# PN74xxAU register map
File version: 2
CPU: CM0 r0p0, little endian, no MPU, no FPU, 2 interrupt priority bits
Registers are 32-bit, read-write, reset 0x0 unless marked. A register's access mark holds for its fields unless they carry their own. Offsets are from the block's base; [hi:lo] are bit positions; {n}, {i} and the like mark numbered series.

## PCR — Power Control and Reset
Base 0x40024000
{0x0+4i} PCR_GPREG{i}_REG (i=0..2) — General purpose register {i} for SW
  [31:0] PCR_GPREG{i} — General Purpose Register for SW
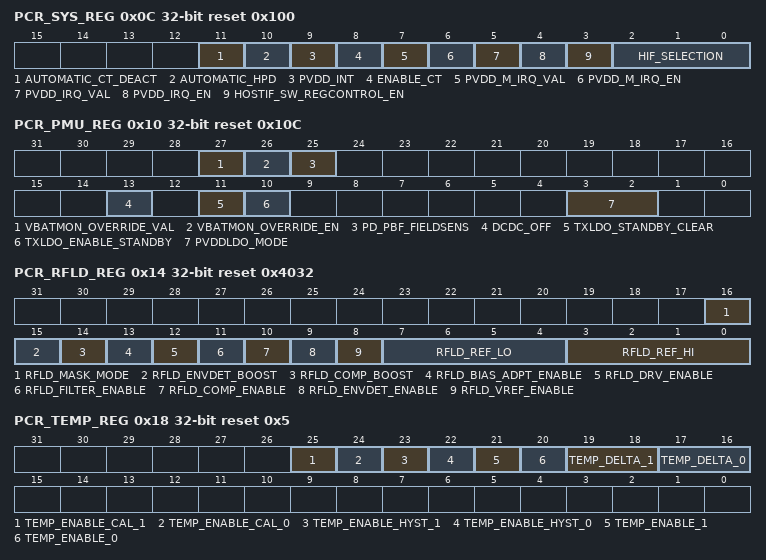
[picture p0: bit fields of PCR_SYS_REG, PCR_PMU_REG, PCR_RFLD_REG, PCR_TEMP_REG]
0x0C PCR_SYS_REG reset 0x100 — System configuration like Hostif selection and CT enabling
  [11] AUTOMATIC_CT_DEACT — Enables automatic initiation of ct deactivation sequence when VBUSP voltage goes below programmed range.
  [10] AUTOMATIC_HPD — Enables PCR to go automatically into HPD state when the VBUS voltage goes below programmed voltage of 2.3V/2.7V
  [9] PVDD_INT — Indicatres that PVDD is being supplied using internal PVDD LDO
  [8] ENABLE_CT — enables the Contact interface.
  [7] PVDD_M_IRQ_VAL — Selects the PVDD_M voltage trigger level
  [6] PVDD_M_IRQ_EN — Enables the PVDD_M IRQ
  [5] PVDD_IRQ_VAL — Selects the PVDD voltage trigger level
  [4] PVDD_IRQ_EN — Enables the PVDD IRQ
  [3] HOSTIF_SW_REGCONTROL_EN — Enabled control of USB D+,D- from ATX_A/B registers
  [2:0] HIF_SELECTION — Host Interface Selection
0x10 PCR_PMU_REG reset 0x10C — PMU interface. For LDO, bandgap,DCDC configuration and sequences
  [27] VBATMON_OVERRIDE_VAL — 0 for 2.7V and 1 for 2.3V
  [26] VBATMON_OVERRIDE_EN — enable for vbus monitor
  [25] PD_PBF_FIELDSENS — Enable for pbf_pd_fieldsens
  [13] DCDC_OFF — To set the DC-DC in high impedance state enabling the testing of VCCLDO. VUP will be forced from outside.
  [11] TXLDO_STANDBY_CLEAR — TXLDO clear standby mode
  [10] TXLDO_ENABLE_STANDBY — TXLDO enable standby mode
  [3:2] PVDDLDO_MODE — Selects pvddldo mode normal/low power/soft start/power down
0x14 PCR_RFLD_REG reset 0x4032 — CLIF configuration
  [16] RFLD_MASK_MODE — RFU
  [15] RFLD_ENVDET_BOOST — Higher bias current for the env-detector
  [14] RFLD_COMP_BOOST — Higher bias current for comparator
  [13] RFLD_BIAS_ADPT_ENABLE — Enable of automatic bias current regulation
  [12] RFLD_DRV_ENABLE — Enable the chopper clock driver for the RF Level Detector.
  [11] RFLD_FILTER_ENABLE — Enable the chopper fillter for RF Level Detector
  [10] RFLD_COMP_ENABLE — Enable of RFLD comparator
  [9] RFLD_ENVDET_ENABLE — Enable of RFLD envelope detector
  [8] RFLD_VREF_ENABLE — Enable for RFLD reference voltage generator
  [7:4] RFLD_REF_LO — Higher Reference Value for RF Level Detector
  [3:0] RFLD_REF_HI — Lower Reference Value for RF Level Detector
0x18 PCR_TEMP_REG reset 0x5 — Temperature sensor calibration information
  [25] TEMP_ENABLE_CAL_1 — Enable Calibration of Temperature Sensor 2
  [24] TEMP_ENABLE_CAL_0 — Enable Calibration of Temperature Sensor 1
  [23] TEMP_ENABLE_HYST_1 — Enable Hystere of Temperature Sensor 2
  [22] TEMP_ENABLE_HYST_0 — Enable Hystere of Temperature Sensor 1
  [21] TEMP_ENABLE_1 — Enable Temp Sensor 2
  [20] TEMP_ENABLE_0 — Enable Temp Sensor 1
  [19:18] TEMP_DELTA_1 — selects temperatur threshold detection for temperature sensor 2
  [17:16] TEMP_DELTA_0 — selects temperatur threshold detection for temperature sensor 1
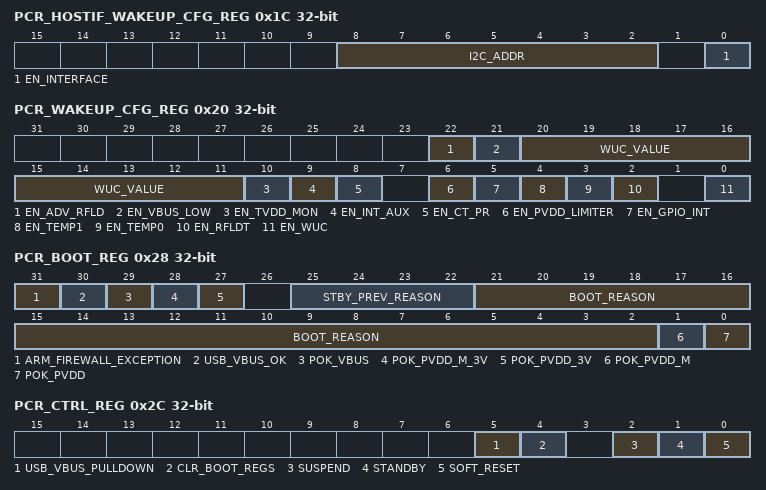
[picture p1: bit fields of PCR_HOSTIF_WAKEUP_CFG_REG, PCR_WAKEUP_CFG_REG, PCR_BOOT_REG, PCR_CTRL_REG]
0x1C PCR_HOSTIF_WAKEUP_CFG_REG — Configuring Wakeup source for Standby and Suspend
  [8:2] I2C_ADDR — I2C address for wakeup
  [0] EN_INTERFACE — Enable Wakeup Host Interface
0x20 PCR_WAKEUP_CFG_REG — Configuring Wakeup source for Standby and Suspend
  [22] EN_ADV_RFLD — Enable Advanced RF Level Detector
  [21] EN_VBUS_LOW — Enable wakeup when vbus goes low
  [20:11] WUC_VALUE — Wakeup Timer Value
  [10] EN_TVDD_MON — Enable wakeup from TVDD 5V monitor
  [9] EN_INT_AUX — Enable wakeup is TDA (CTUART) gives an level high interrupt
  [8] EN_CT_PR — Enables wakeup if card is detected.
  [6] EN_PVDD_LIMITER — Enables wakeup if PVDD current limiter is risen
  [5] EN_GPIO_INT — Enables wakeup if GPIO gives any input
  [4] EN_TEMP1 — Enable Temperature 1 Error Wakeup
  [3] EN_TEMP0 — Enable Temperature 0 Error Wakeup
  [2] EN_RFLDT — Enable Wakeup RF Level Detector
  [0] EN_WUC — Enable Wakeup Timer
0x24 PCR_GPIO_WAKEUP_CFG_REG reset 0xFF — Configuring Wakeup source for Standby and Suspend
  [11:0] GPIO_WAKEUP_ENABLE — enables wakeup by the corresponding gpio 0-->gpio1 1-->gpio2 , e.t.c.
0x28 PCR_BOOT_REG — Bootup register with important values to be checked during bootup
  [31] ARM_FIREWALL_EXCEPTION — Indicates arm firewall exception occurred.
  [30] USB_VBUS_OK ro — Indicator for USB_VBUS is ok
  [29] POK_VBUS ro — Indicator when VBUS > VBUSCritical when VBUSMonitor is enabled
  [28] POK_PVDD_M_3V ro — Indicator for more than 3V at PVDD_M pin
  [27] POK_PVDD_3V ro — Indicator for more than 3V at PVDD pin
  [25:22] STBY_PREV_REASON ro — Standby Prevention Reason
  [21:2] BOOT_REASON ro — Bootup Reason
  [1] POK_PVDD_M ro — Indicator if PVDD_m is available
  [0] POK_PVDD ro — Indicator if PVDD is available
0x2C PCR_CTRL_REG — Control register to enable standby/suspend/soft-restart/clearing boot register
  [5] USB_VBUS_PULLDOWN — Enables the internal pulldown resistance to pulldown the USB_VBUS
  [4] CLR_BOOT_REGS wo — Clearing Standby Prevention and Bootup register values in the PCR_BOOT_REG register
  [2] SUSPEND wo — Enables entering suspend mode
  [1] STANDBY wo — Entering Standby Mode
  [0] SOFT_RESET wo — Trigger Soft Reset Source
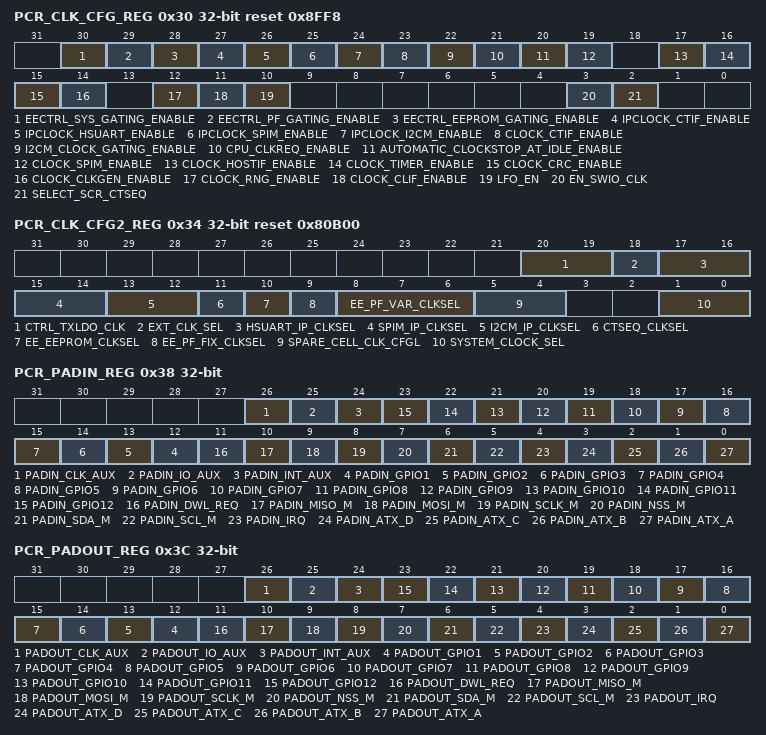
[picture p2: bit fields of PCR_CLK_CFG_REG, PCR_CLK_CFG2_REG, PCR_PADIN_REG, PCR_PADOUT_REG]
0x30 PCR_CLK_CFG_REG reset 0x8FF8 — Enable, gating, division value selection for clocks going to different Ips
  [30] EECTRL_SYS_GATING_ENABLE — EEPROM controller system clock gating enable
  [29] EECTRL_PF_GATING_ENABLE — EEPROM controller page flash clock gating enable
  [28] EECTRL_EEPROM_GATING_ENABLE — EEPROM controller automatic clock gating enable
  [27] IPCLOCK_CTIF_ENABLE — Contact interface IP clock enable
  [26] IPCLOCK_HSUART_ENABLE — High speed uart IP clock enable
  [25] IPCLOCK_SPIM_ENABLE — SPI master uart IP clock enable
  [24] IPCLOCK_I2CM_ENABLE — I2C master uart IP clock enable
  [23] CLOCK_CTIF_ENABLE — Enable contact source for Contact interface
  [22] I2CM_CLOCK_GATING_ENABLE — Enable clock source for I2C master
  [21] CPU_CLKREQ_ENABLE — Enable the automatic clock request for ROM and RAM via the CPU
  [20] AUTOMATIC_CLOCKSTOP_AT_IDLE_ENABLE — Enable automatic clock gating for CRC, EECTRL, RNG and ROM when cpu is in idle mode
  [19] CLOCK_SPIM_ENABLE — enable clock source for SPIM
  [17] CLOCK_HOSTIF_ENABLE — enable clock source for HOSTIF
  [16] CLOCK_TIMER_ENABLE — enable clock source for TIMER
  [15] CLOCK_CRC_ENABLE — enable clock source for CRC
  [14] CLOCK_CLKGEN_ENABLE — enable clock source for CLKGEN
  [12] CLOCK_RNG_ENABLE — enable clock source for RNG
  [11] CLOCK_CLIF_ENABLE — enable clock source for CLIF
  [10] LFO_EN — Enable LFO
  [3] EN_SWIO_CLK — Enables the SWIO clock
  [2] SELECT_SCR_CTSEQ — Selects the clock source for the system clock generation 0 ... clkXTAL (27.12 MHz) 1 ... clkPLL/2 (24MHz)
0x34 PCR_CLK_CFG2_REG reset 0x80B00 — Select lines for Clock muxes , between different frequencies or between different division values
  [20:19] CTRL_TXLDO_CLK — TXLDO clock division select. 00->LFO/1 , 01-> LFO/2 , 10->LFO/4 , 11->LFO/8
  [18] EXT_CLK_SEL — Selects between XTAL clock and External clock. 0...XTAL , 1...external clock
  [17:16] HSUART_IP_CLKSEL — Selects ip clock divider value for hsuart. 00...xtal/1 01...xtal/2 10...xtal/4 11...RFU
  [15:14] SPIM_IP_CLKSEL — Selects ip clock divider value for spim. 00...xtal/1 01...xtal/2 10...xtal/4 11...RFU
  [13:12] I2CM_IP_CLKSEL — Selects ip clock divider value for spim. 00...xtal/1 01...xtal/2 10...xtal/4 11...RFU
  [11] CTSEQ_CLKSEL — 0...+10 1...+82
  [10] EE_EEPROM_CLKSEL — Selects the divider value for the lfo clock for the EEPROM module 0 ... LFO/1 1...lfo/4
  [9] EE_PF_FIX_CLKSEL — Selects between divided xtal value and gpio1 test clock 0 ... gpio1clk/1 (only for test purpose) 1...xtal-clk/32
  [8:6] EE_PF_VAR_CLKSEL — Selects between gpio1 clock and xtal divided clocks for PageFlash module. 0 ... gpio1clk/1 (only for test purpose) 1 ... Xtal-clk/4 2 ... Xtal-clk/8 3 ... Xtal-clk/16 4...Xtal-clk/32 5--7 RFU
  [5:4] SPARE_CELL_CLK_CFGL — Spare cells to be used for clock config
  [1:0] SYSTEM_CLOCK_SEL — Selects the divider for the system clock . 00...Divby1 01...DIVby2 10...DIVby4 11...RESERVED
0x38 PCR_PADIN_REG ro — Store value on input pasd into this register
  [26] PADIN_CLK_AUX — Input value for CLK_AUX
  [25] PADIN_IO_AUX — Input value for IO_AUX
  [24] PADIN_INT_AUX — Input value for INT_AUX
  [n+11] PADIN_GPIO{n} (n=1..12) — Input value for GPIO{n}
  [11] PADIN_DWL_REQ — Input value for DWL_REQ
  [10] PADIN_MISO_M — Input value for MISO_M
  [9] PADIN_MOSI_M — Input value for MOSI_M
  [8] PADIN_SCLK_M — Input value for SCLK_M
  [7] PADIN_NSS_M — Input value for NSS_M
  [6] PADIN_SDA_M — Input Value SDA_M
  [5] PADIN_SCL_M — Input Value SCL_M
  [4] PADIN_IRQ — input value for IRQ
  [3] PADIN_ATX_D — Input Value ATX_D
  [2] PADIN_ATX_C — Input Value ATX_C
  [1] PADIN_ATX_B — Input Value ATX_B
  [0] PADIN_ATX_A — Input Value ATX_A
0x3C PCR_PADOUT_REG — Output value to be driven onto Output pads stored here
  [26] PADOUT_CLK_AUX — Output value for CLK_AUX
  [25] PADOUT_IO_AUX — Output value for IO_AUX
  [24] PADOUT_INT_AUX — Output value for INT_AUX
  [n+11] PADOUT_GPIO{n} (n=1..12) — Output value for GPIO{n}
  [11] PADOUT_DWL_REQ — Output value for DWL_REQ
  [10] PADOUT_MISO_M — Output value for MISO_M
  [9] PADOUT_MOSI_M — Output value for MOSI_M
  [8] PADOUT_SCLK_M — Output value for SCLK_M
  [7] PADOUT_NSS_M — Output value for NSS_M
  [6] PADOUT_SDA_M — Output Value SDA_M
  [5] PADOUT_SCL_M — Output Value SCL_M
  [4] PADOUT_IRQ — Output value for IRQ
  [3] PADOUT_ATX_D — Output Value ATX_D
  [2] PADOUT_ATX_C — Output Value ATX_C
  [1] PADOUT_ATX_B — Output Value ATX_B
  [0] PADOUT_ATX_A — Output Value ATX_A
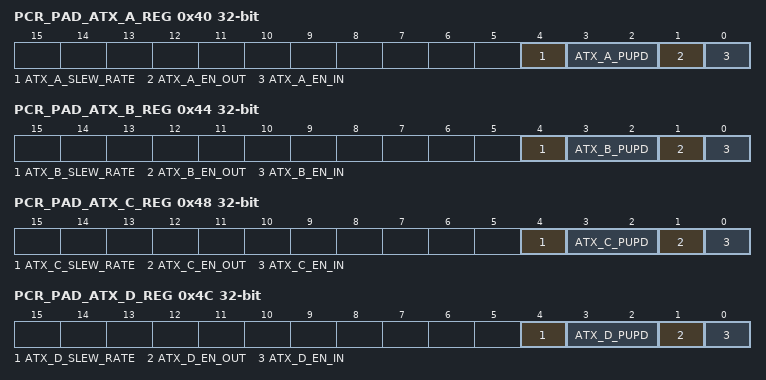
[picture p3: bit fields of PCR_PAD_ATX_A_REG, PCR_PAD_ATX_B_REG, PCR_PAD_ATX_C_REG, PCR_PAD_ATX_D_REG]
0x40 PCR_PAD_ATX_A_REG — Host if pad: i2c_scl/spi_nss/hsu_rx/usb_dp/smb_cl
  [4] ATX_A_SLEW_RATE — Select Driver Strength for ATX_A
  [3:2] ATX_A_PUPD — Enable PullUp/Down on ATX_A
  [1] ATX_A_EN_OUT — Enables Output driver for ATX_A
  [0] ATX_A_EN_IN — Enables Input Driver for ATX_A
0x44 PCR_PAD_ATX_B_REG — Host if pad: i2c_sda/spi_mosi/hsu_tx/usb_dm/smb_da
  [4] ATX_B_SLEW_RATE — Select Driver Strength for ATX_B
  [3:2] ATX_B_PUPD — Enable PullUp/Down on ATX_B
  [1] ATX_B_EN_OUT — Enables Output driver for ATX_B
  [0] ATX_B_EN_IN — Enables Input Driver for ATX_B
0x48 PCR_PAD_ATX_C_REG — Host if pad: i2c_adr0/spi_miso/hsu_rts_n/usb-N.A/smbalert
  [4] ATX_C_SLEW_RATE — Select Driver Strength for ATX_C
  [3:2] ATX_C_PUPD — Enable PullUp/Down on ATX_C
  [1] ATX_C_EN_OUT — Enables Output driver for ATX_C
  [0] ATX_C_EN_IN — Enables Input Driver for ATX_C
0x4C PCR_PAD_ATX_D_REG — Host if pad: i2cadr1/spi_sck/hsu_cts_n/usb-N.A/smb-N.A
  [4] ATX_D_SLEW_RATE — Select Driver Strength for ATX_D
  [3:2] ATX_D_PUPD — Enable PullUp/Down on ATX_D
  [1] ATX_D_EN_OUT — Enables Output driver for ATX_D
  [0] ATX_D_EN_IN — Enables Input Driver for ATX_D
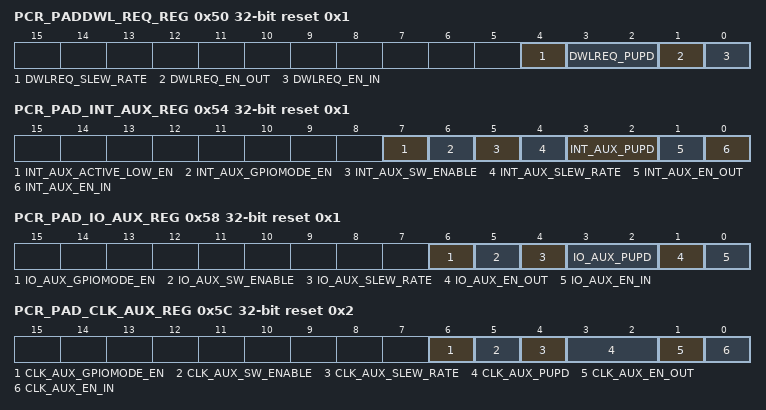
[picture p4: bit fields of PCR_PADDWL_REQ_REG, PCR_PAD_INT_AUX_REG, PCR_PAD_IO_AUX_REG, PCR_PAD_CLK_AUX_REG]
0x50 PCR_PADDWL_REQ_REG reset 0x1 — DWL_REQ pad configuration
  [4] DWLREQ_SLEW_RATE — Select Driver Strength for DWLREQ
  [3:2] DWLREQ_PUPD — Enable PullUp/Down on DWLREQ
  [1] DWLREQ_EN_OUT — Enables Output driver for DWLREQ
  [0] DWLREQ_EN_IN — Enables Input Driver for DWLREQ
0x54 PCR_PAD_INT_AUX_REG reset 0x1 — INT_AUX pad configuration
  [7] INT_AUX_ACTIVE_LOW_EN — Configures INT_AUX to be interpretted as active low signal
  [6] INT_AUX_GPIOMODE_EN — Puts the INT_AUX PAD in GPIO mode ( By default in I2C mode)
  [5] INT_AUX_SW_ENABLE — Enabling software register control for INT_AUX
  [4] INT_AUX_SLEW_RATE — Select Driver Strength for INT_AUX
  [3:2] INT_AUX_PUPD — Enable PullUp/Down on INT_AUX
  [1] INT_AUX_EN_OUT — Enables Output driver for INT_AUX
  [0] INT_AUX_EN_IN — Enables Input Driver for INT_AUX
0x58 PCR_PAD_IO_AUX_REG reset 0x1 — IO_AUX pad configuration
  [6] IO_AUX_GPIOMODE_EN — Puts the IO_AUX PAD in GPIO mode ( By default in I2C mode)
  [5] IO_AUX_SW_ENABLE — Enabling software register control for IO_AUX
  [4] IO_AUX_SLEW_RATE — Select Driver Strength for IO_AUX
  [3:2] IO_AUX_PUPD — Enable PullUp/Down on IO_AUX
  [1] IO_AUX_EN_OUT — Enables Output driver for IO_AUX
  [0] IO_AUX_EN_IN — Enables Input Driver for IO_AUX
0x5C PCR_PAD_CLK_AUX_REG reset 0x2 — CLK_AUX pad configuration
  [6] CLK_AUX_GPIOMODE_EN — Enabling CLK_AUX pad in GPIO mode ( By default in I2C mode)
  [5] CLK_AUX_SW_ENABLE — Enabling software register control for CLK_AUX
  [4] CLK_AUX_SLEW_RATE — Select Driver Strength for CLK_AUX
  [3:2] CLK_AUX_PUPD — Enable PullUp/Down on CLK_AUX
  [1] CLK_AUX_EN_OUT — Enables Output driver for CLK_AUX
  [0] CLK_AUX_EN_IN — Enables Input Driver for CLK_AUX
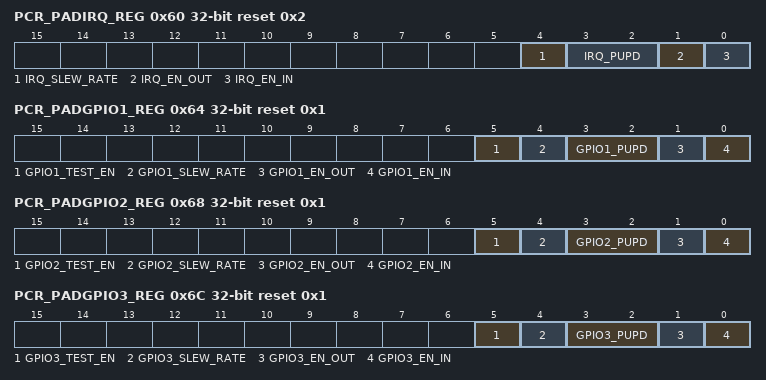
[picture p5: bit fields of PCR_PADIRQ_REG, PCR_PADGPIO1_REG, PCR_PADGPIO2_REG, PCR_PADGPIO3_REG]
0x60 PCR_PADIRQ_REG reset 0x2 — IRQ pad configuration
  [4] IRQ_SLEW_RATE — Select Driver Strength for IRQ
  [3:2] IRQ_PUPD — Enable PullUp/Down on IRQ
  [1] IRQ_EN_OUT — Enables Output driver for IRQ
  [0] IRQ_EN_IN — Enables Input Driver for IRQ
0x64 PCR_PADGPIO1_REG reset 0x1 — GPIO1 pad configuration
  [5] GPIO1_TEST_EN — Indicating that the GPIO 1 pad is giving clock
  [4] GPIO1_SLEW_RATE — Select Driver Strength for GPIO1
  [3:2] GPIO1_PUPD — Enable PullUp/Down on GPIO1
  [1] GPIO1_EN_OUT — Enables Output driver for GPIO1
  [0] GPIO1_EN_IN — Enables Input Driver for GPIO1
0x68 PCR_PADGPIO2_REG reset 0x1 — GPIO2 pad configuration
  [5] GPIO2_TEST_EN — Indicating the GPIO2 pad is giving clock
  [4] GPIO2_SLEW_RATE — Select Driver Strength for GPIO2
  [3:2] GPIO2_PUPD — Enable PullUp/Down on GPIO2
  [1] GPIO2_EN_OUT — Enables Output driver for GPIO2
  [0] GPIO2_EN_IN — Enables Input Driver for GPIO2
0x6C PCR_PADGPIO3_REG reset 0x1 — GPIO3 pad configuration
  [5] GPIO3_TEST_EN — Indicating the GPIO3 pad is used for testing of clock
  [4] GPIO3_SLEW_RATE — Select Driver Strength for GPIO3
  [3:2] GPIO3_PUPD — Enable PullUp/Down on GPIO3
  [1] GPIO3_EN_OUT — Enables Output driver for GPIO3
  [0] GPIO3_EN_IN — Enables Input Driver for GPIO3
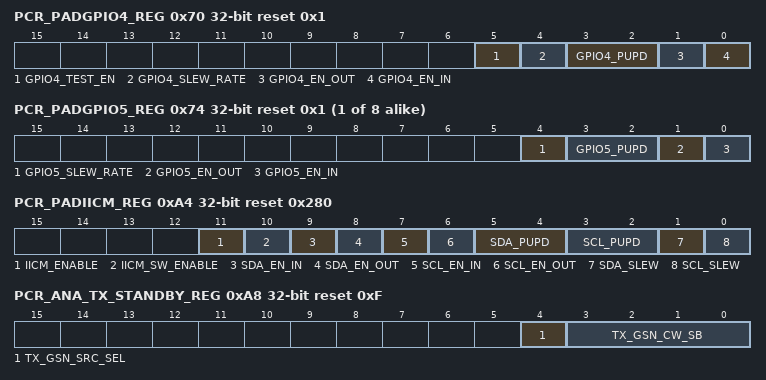
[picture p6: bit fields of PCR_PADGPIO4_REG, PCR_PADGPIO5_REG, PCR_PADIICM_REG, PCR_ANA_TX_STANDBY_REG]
0x70 PCR_PADGPIO4_REG reset 0x1 — GPIO4 pad configuration
  [5] GPIO4_TEST_EN — Indicating the GPIO4 pad is used for testing of clock
  [4] GPIO4_SLEW_RATE — Select Driver Strength for GPIO4
  [3:2] GPIO4_PUPD — Enable PullUp/Down on GPIO4
  [1] GPIO4_EN_OUT — Enables Output driver for GPIO4
  [0] GPIO4_EN_IN — Enables Input Driver for GPIO4
{0x60+4i} PCR_PADGPIO{i}_REG reset 0x1 (i=5..12) — GPIO{i} pad configuration
  [4] GPIO{i}_SLEW_RATE — Select Driver Strength for GPIO{i}
  [3:2] GPIO{i}_PUPD — Enable PullUp/Down on GPIO{i}
  [1] GPIO{i}_EN_OUT — Enables Output driver for GPIO{i}
  [0] GPIO{i}_EN_IN — Enables Input Driver for GPIO{i}
0xA4 PCR_PADIICM_REG reset 0x280 — I2C master pad configuration
  [11] IICM_ENABLE — Enabling I2C master, disabling this allows programming I2C master pads as GPIO if IICM_SW_ENABLE =1 ( Software control mode)
  [10] IICM_SW_ENABLE — Enables register control of I2C pads
  [9] SDA_EN_IN — Enables input driver for SDA
  [8] SDA_EN_OUT — Enables output driver for SDA
  [7] SCL_EN_IN — Enables input driver for SCL
  [6] SCL_EN_OUT — Enables output driver for SCL
  [5:4] SDA_PUPD — Enables pullup/down functionality on SDA
  [3:2] SCL_PUPD — Enables pullup/down functionality on SCL
  [1] SDA_SLEW — SDA Slew Rate
  [0] SCL_SLEW — SCL Slew Rate
0xA8 PCR_ANA_TX_STANDBY_REG reset 0xF — CLIF standby GSN value selection
  [4] TX_GSN_SRC_SEL — Source of GSN value (0...PCR, 1...CLIF)
  [3:0] TX_GSN_CW_SB — GSN Value for Standby Mode
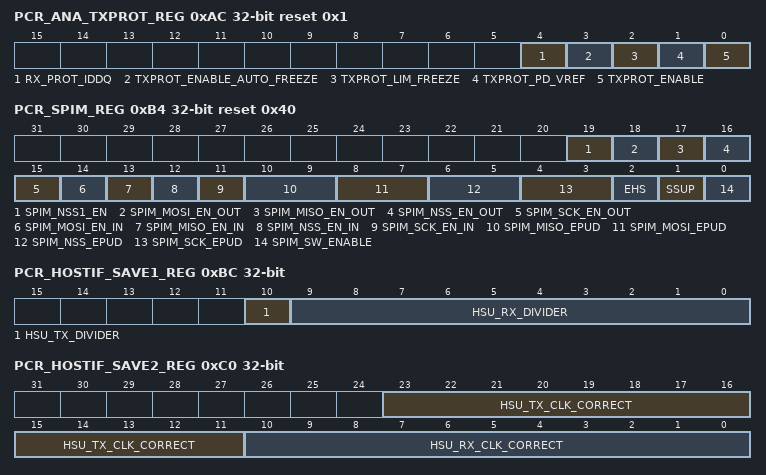
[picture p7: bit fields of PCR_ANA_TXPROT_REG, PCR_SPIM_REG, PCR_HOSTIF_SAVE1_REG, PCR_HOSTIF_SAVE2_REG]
0xAC PCR_ANA_TXPROT_REG reset 0x1 — CLIF configuration related to powerdown
  [4] RX_PROT_IDDQ — Set RX protection to power down for Iddq measurement
  [3] TXPROT_ENABLE_AUTO_FREEZE — Enable automatic freeze during typeB demodulation: typeB_det =1 -> freeze; else -> no freeze
  [2] TXPROT_LIM_FREEZE — freeze limiter impedance, active high
  [1] TXPROT_PD_VREF — power down refernce voltage generation for tx-prot
  [0] TXPROT_ENABLE — enables tx protection
0xB4 PCR_SPIM_REG reset 0x40 — SPIM master pad configuration
  [19] SPIM_NSS1_EN — SPIM master second slave enabled : Slave 1, Slave0 enabled by default.
  [18] SPIM_MOSI_EN_OUT — SW control for SPIM_MOSI ECS
  [17] SPIM_MISO_EN_OUT — SW control for SPIM_MISO ECS
  [16] SPIM_NSS_EN_OUT — SW control for SPIM_NSS ECS
  [15] SPIM_SCK_EN_OUT — SW control for SPIM_SCK ECS
  [14] SPIM_MOSI_EN_IN — SW control for SPIM_MOSI ENZI ( ENZI = ~EN_IN)
  [13] SPIM_MISO_EN_IN — SW control for SPIM_MISO ENZI ( ENZI = ~EN_IN)
  [12] SPIM_NSS_EN_IN — SW control for SPIM_NSS ENZI ( ENZI = ~EN_IN)
  [11] SPIM_SCK_EN_IN — SW control for SPIM_SCK ENZI ( ENZI = ~EN_IN)
  [10:9] SPIM_MISO_EPUD — SW control for SPIM_MISO EPUD/EPD
  [8:7] SPIM_MOSI_EPUD — SW control for SPIM_MOSI EPUD/EPD
  [6:5] SPIM_NSS_EPUD — SW control for SPIM_NSS EPUD/EPD
  [4:3] SPIM_SCK_EPUD — SW control for SPIM_SCK EPUD/EPD
  [2] EHS — Select dirver strength for SPIM pads
  [1] SSUP — Supply voltage for SPIM pads
  [0] SPIM_SW_ENABLE — Enables Pad configuration for SPI master
0xB8 PCR_CTIF_REG — CTIF presense detection pull-up
  [0] CT_PRES_ENABLE_PUP ro — Value of ct_pres_enable_pup_i coming from CTIF is latched and is used to detect card activity during standby and suspend modes if CTIF is enabled as wakeup source
0xBC PCR_HOSTIF_SAVE1_REG — Host interface Tx/RX divider value storage during standby
  [10] HSU_TX_DIVIDER — TX Divider save (only save reg for stby)
  [9:0] HSU_RX_DIVIDER — RX Divider save (only save reg for stby)
0xC0 PCR_HOSTIF_SAVE2_REG — Host interface clock value storage during standby
  [23:11] HSU_TX_CLK_CORRECT — Clock correction for TX (only save reg for stby)
  [10:0] HSU_RX_CLK_CORRECT — Clock correction for RX (only save reg for stby)
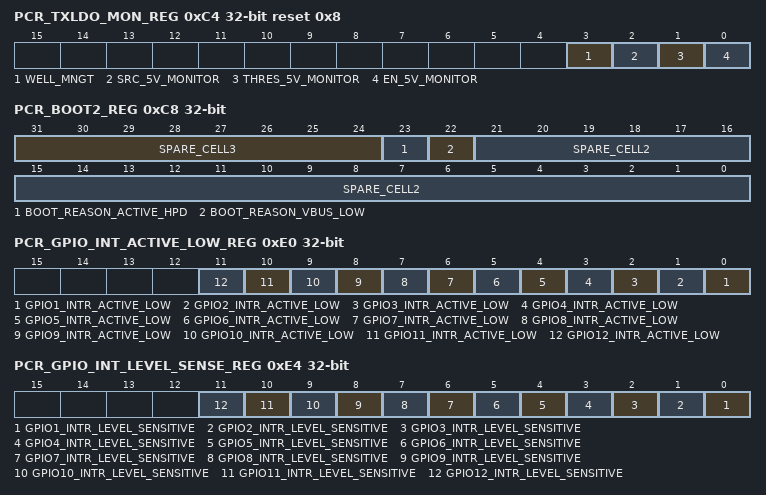
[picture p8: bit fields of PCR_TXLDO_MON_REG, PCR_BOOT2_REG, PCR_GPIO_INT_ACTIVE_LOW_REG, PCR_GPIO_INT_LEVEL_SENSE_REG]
0xC4 PCR_TXLDO_MON_REG reset 0x8 — TXLDO sequence management
  [3] WELL_MNGT — TXLDO well mngt
  [2] SRC_5V_MONITOR — Input of the 5V monitor.
  [1] THRES_5V_MONITOR — Comparator threshold selector
  [0] EN_5V_MONITOR — Enable the 5V monitor on TVDD
0xC8 PCR_BOOT2_REG — General Purpose Register 3 for SW
  [31:24] SPARE_CELL3 — Third set of spare cells.
  [23] BOOT_REASON_ACTIVE_HPD ro — Boot because of coming out of ACTIVE_HPD
  [22] BOOT_REASON_VBUS_LOW ro — Boot because of VBUS going low in suspend or standby.
  [21:0] SPARE_CELL2 — Second set of space cells
{0xC0+4i} PCR_GPREG{i}_REG (i=3..7) — General Purpose Register {i} for SW
  [31:0] PCR_GPREG{i} — General Purpose Register for SW
0xE0 PCR_GPIO_INT_ACTIVE_LOW_REG — Register to program is gpio interrupts are active low level/ falling edge sensitive
  [n-1] GPIO{n}_INTR_ACTIVE_LOW (n=1..12) — Indicates if GPIO{n} interrupts are active low/falling edge. 0--> Active_high/Rising edge; 1--> Active_low/falling edge.
0xE4 PCR_GPIO_INT_LEVEL_SENSE_REG — Register to program if gpio interrupts are level sensitive
  [n-1] GPIO{n}_INTR_LEVEL_SENSITIVE (n=1..12) — Indicates if GPIO{n} interrupts are level sensitive/edge sensitive. 0--> Edge sensitive; 1--> Level sensitive.
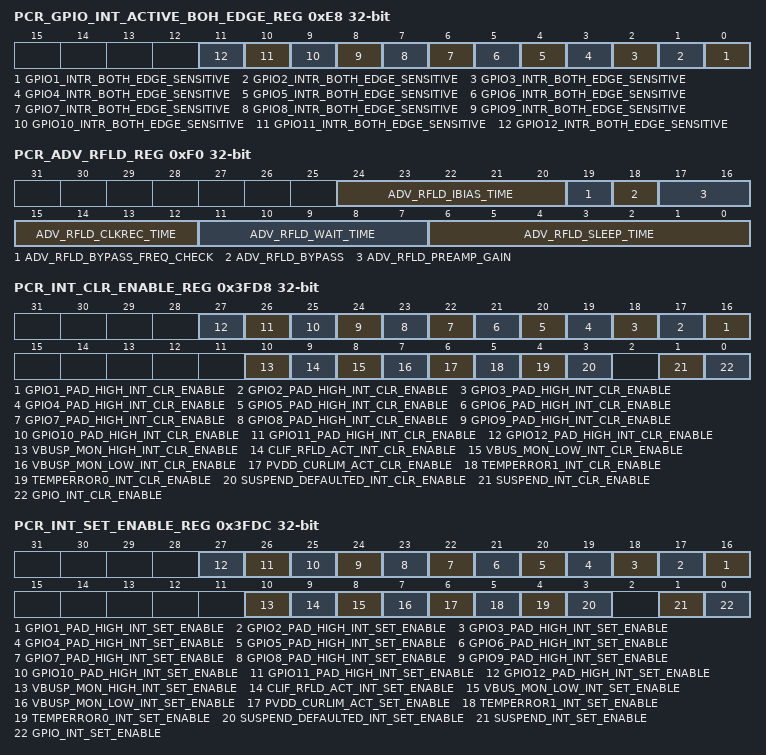
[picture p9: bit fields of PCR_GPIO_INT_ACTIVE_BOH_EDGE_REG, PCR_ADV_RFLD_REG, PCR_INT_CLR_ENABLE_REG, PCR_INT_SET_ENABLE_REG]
0xE8 PCR_GPIO_INT_ACTIVE_BOH_EDGE_REG — Register to program if gpio interrupts are both edge sensitive
  [n-1] GPIO{n}_INTR_BOTH_EDGE_SENSITIVE (n=1..12) — Indicates if GPIO{n} interrupts are both positive and negative edge triggered. 0--> Not both edge triggered; 1--> both positive edge and negative edge triggered.
0xEC PCR_SELECT_SYSTEMCLOCK reset 0x1 — Register to program the source for system clock
  [2:0] SELECT_SYSTEMCLOCK — Selects the clock source :: 3'b001...clkHFO (20 MHz) 3'b010...clkUSBPLL/2 (24MHz) 3'b100...clkXtal (27.12MHz) OthersINVALID
0xF0 PCR_ADV_RFLD_REG — Register for configuring advanced RFLD detection FSM
  [24:20] ADV_RFLD_IBIAS_TIME — Ibias Bootup Time
  [19] ADV_RFLD_BYPASS_FREQ_CHECK — Bypass the digital frequency check in case of malfunction of frequency check
  [18] ADV_RFLD_BYPASS — Enable Bypass for PreAmplifier. To be set if normal RF Level detector is used for
  [17:16] ADV_RFLD_PREAMP_GAIN — Gain Seting for PreAmplifier
  [15:12] ADV_RFLD_CLKREC_TIME — Bootup Time for Clock Recovery. Defines time between switching on the Clock Recovery until Frequency Check is enabled
  [11:7] ADV_RFLD_WAIT_TIME — Bootup Time for Advanced RF Level Detector. Defines time between switching on the RF Level Detector until Field is checked.
  [6:0] ADV_RFLD_SLEEP_TIME — Defines the Sleep Time (# LFO cycles) in the polling circuit where the Advanced RF Level Detector is switched off.
0x3FD8 PCR_INT_CLR_ENABLE_REG wo — Interrupt clear enable
  [n+15] GPIO{n}_PAD_HIGH_INT_CLR_ENABLE (n=1..12) — GPIO{n} pad going high interrupt clear enable
  [10] VBUSP_MON_HIGH_INT_CLR_ENABLE — VBUSP monitor going high interrupt clear enable
  [9] CLIF_RFLD_ACT_INT_CLR_ENABLE — Clif RF field activity observed interrupt clear enable
  [8] VBUS_MON_LOW_INT_CLR_ENABLE — VBUS monitor going low interrupt clear enable
  [7] VBUSP_MON_LOW_INT_CLR_ENABLE — VBUSP monitor going low interrupt clear enable
  [6] PVDD_CURLIM_ACT_CLR_ENABLE — PVDD current limiter active interrupt clear enable.
  [5] TEMPERROR1_INT_CLR_ENABLE — Temperature error 1 interrupt clear enable
  [4] TEMPERROR0_INT_CLR_ENABLE — Temperature error 0 interrupt clear enable
  [3] SUSPEND_DEFAULTED_INT_CLR_ENABLE — Suspend defaulted interrupt clear enable
  [1] SUSPEND_INT_CLR_ENABLE — Suspend interrupt clear enable.
  [0] GPIO_INT_CLR_ENABLE — GPIO interrupt clear enable
0x3FDC PCR_INT_SET_ENABLE_REG wo — Interrupt set enable
  [n+15] GPIO{n}_PAD_HIGH_INT_SET_ENABLE (n=1..12) — GPIO{n} pad going high interrupt set enable
  [10] VBUSP_MON_HIGH_INT_SET_ENABLE — VBUSP monitor going high interrupt set enable
  [9] CLIF_RFLD_ACT_INT_SET_ENABLE — Clif RF field activity observed interrupt set enable
  [8] VBUS_MON_LOW_INT_SET_ENABLE — VBUS monitor going low interrupt set enable
  [7] VBUSP_MON_LOW_INT_SET_ENABLE — VBUSP monitor going low interrupt set enable
  [6] PVDD_CURLIM_ACT_SET_ENABLE — PVDD current limiter active interrupt set enable.
  [5] TEMPERROR1_INT_SET_ENABLE — Temperature error 1 interrupt set enable
  [4] TEMPERROR0_INT_SET_ENABLE — Temperature error 0 interrupt set enable
  [3] SUSPEND_DEFAULTED_INT_SET_ENABLE — Suspend defaulted interrupt set enable
  [1] SUSPEND_INT_SET_ENABLE — Suspend interrupt set enable.
  [0] GPIO_INT_SET_ENABLE — GPIO interrupt clear enable
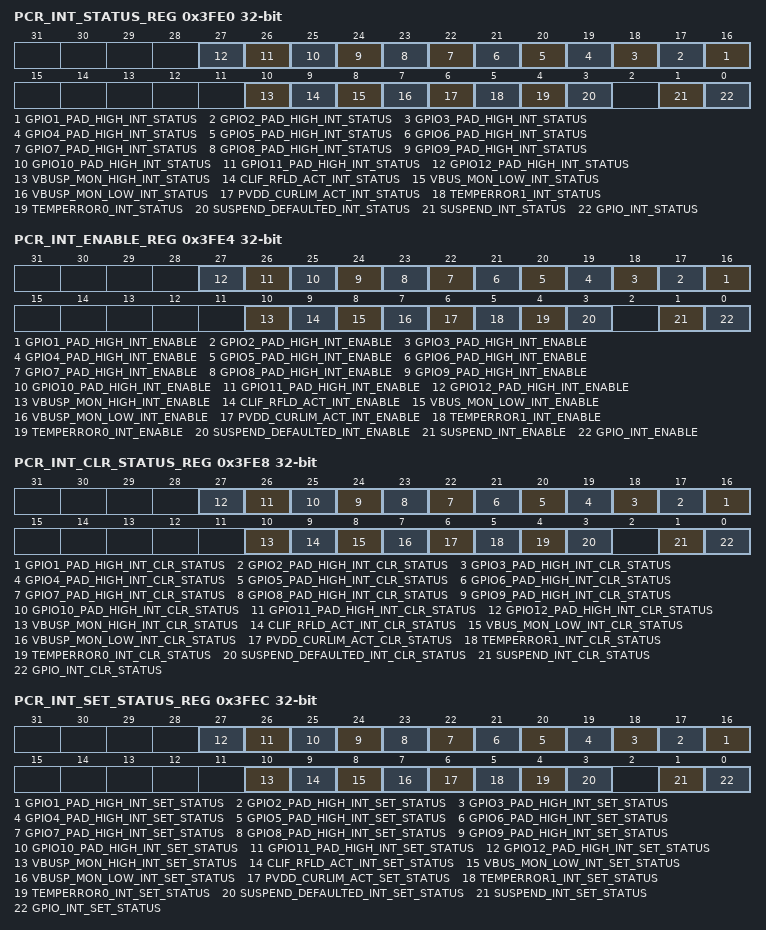
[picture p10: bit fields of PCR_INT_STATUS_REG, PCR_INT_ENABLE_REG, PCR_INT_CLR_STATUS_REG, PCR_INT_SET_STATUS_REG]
0x3FE0 PCR_INT_STATUS_REG ro — Interrupt status
  [n+15] GPIO{n}_PAD_HIGH_INT_STATUS (n=1..12) — GPIO{n} pad going high interrupt status
  [10] VBUSP_MON_HIGH_INT_STATUS — VBUSP monitor going high interrupt status
  [9] CLIF_RFLD_ACT_INT_STATUS — Clif RF field activity observed interrupt status
  [8] VBUS_MON_LOW_INT_STATUS — VBUS monitor going low interrupt clear status
  [7] VBUSP_MON_LOW_INT_STATUS — VBUSP monitor going low interrupt clear status
  [6] PVDD_CURLIM_ACT_INT_STATUS — PVDD current limiter active interrupt status
  [5] TEMPERROR1_INT_STATUS — Temperature error 1 interrupt status
  [4] TEMPERROR0_INT_STATUS — Temperature error 0 interrupt status
  [3] SUSPEND_DEFAULTED_INT_STATUS — Suspend defaulted interrupt status
  [1] SUSPEND_INT_STATUS — Suspend interrupt status.
  [0] GPIO_INT_STATUS — GPIO interrupt clear enable
0x3FE4 PCR_INT_ENABLE_REG ro — Interrupt enable
  [n+15] GPIO{n}_PAD_HIGH_INT_ENABLE (n=1..12) — GPIO{n} pad going high interrupt enable
  [10] VBUSP_MON_HIGH_INT_ENABLE — VBUSP monitor going high interrupt enable
  [9] CLIF_RFLD_ACT_INT_ENABLE — Clif RF field activity observed interrupt enable
  [8] VBUS_MON_LOW_INT_ENABLE — VBUS monitor going low interrupt enable
  [7] VBUSP_MON_LOW_INT_ENABLE — VBUSP monitor going low interrupt enable
  [6] PVDD_CURLIM_ACT_INT_ENABLE — PVDD current limiter active interrupt enable
  [5] TEMPERROR1_INT_ENABLE — Temperature error 1 interrupt enable
  [4] TEMPERROR0_INT_ENABLE — Temperature error 0 interrupt enable
  [3] SUSPEND_DEFAULTED_INT_ENABLE — Suspend defaulted interrupt enable
  [1] SUSPEND_INT_ENABLE — Suspend interrupt enable.
  [0] GPIO_INT_ENABLE — GPIO interrupt clear enable
0x3FE8 PCR_INT_CLR_STATUS_REG wo — Interrupt clear status
  [n+15] GPIO{n}_PAD_HIGH_INT_CLR_STATUS (n=1..12) — GPIO{n} pad going high interrupt clear status
  [10] VBUSP_MON_HIGH_INT_CLR_STATUS — VBUSP monitor going high interrupt clear status
  [9] CLIF_RFLD_ACT_INT_CLR_STATUS — Clif RF field activity observed interrupt clear status
  [8] VBUS_MON_LOW_INT_CLR_STATUS — VBUS monitor going low interrupt clear status
  [7] VBUSP_MON_LOW_INT_CLR_STATUS — VBUSP monitor going low interrupt clear status
  [6] PVDD_CURLIM_ACT_CLR_STATUS — PVDD current limiter active interrupt clear status
  [5] TEMPERROR1_INT_CLR_STATUS — Temperature error 1 interrupt clear status
  [4] TEMPERROR0_INT_CLR_STATUS — Temperature error 0 interrupt clear status
  [3] SUSPEND_DEFAULTED_INT_CLR_STATUS — Suspend defaulted interrupt clear status
  [1] SUSPEND_INT_CLR_STATUS — Suspend interrupt clear status.
  [0] GPIO_INT_CLR_STATUS — GPIO interrupt clear clear status
0x3FEC PCR_INT_SET_STATUS_REG wo — Interrupt set status
  [n+15] GPIO{n}_PAD_HIGH_INT_SET_STATUS (n=1..12) — GPIO{n} pad going high interrupt set status
  [10] VBUSP_MON_HIGH_INT_SET_STATUS — VBUSP monitor going high interrupt set status
  [9] CLIF_RFLD_ACT_INT_SET_STATUS — Clif RF field activity observed interrupt set status
  [8] VBUS_MON_LOW_INT_SET_STATUS — VBUS monitor going low interrupt set status
  [7] VBUSP_MON_LOW_INT_SET_STATUS — VBUSP monitor going low interrupt set status
  [6] PVDD_CURLIM_ACT_SET_STATUS — PVDD current limiter active interrupt set status.
  [5] TEMPERROR1_INT_SET_STATUS — Temperature error 1 interrupt set status
  [4] TEMPERROR0_INT_SET_STATUS — Temperature error 0 interrupt set status
  [3] SUSPEND_DEFAULTED_INT_SET_STATUS — Suspend defaulted interrupt set status
  [1] SUSPEND_INT_SET_STATUS — Suspend interrupt set status.
  [0] GPIO_INT_SET_STATUS — GPIO interrupt clear clear status
